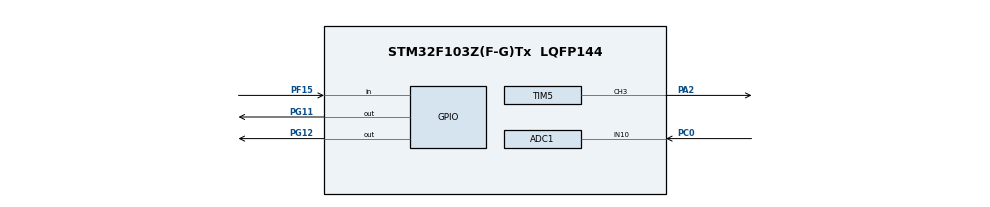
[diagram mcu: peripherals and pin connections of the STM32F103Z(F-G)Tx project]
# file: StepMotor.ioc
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ADC1.Channel-0\#ChannelRegularConversion=ADC_CHANNEL_10
ADC1.NbrOfConversionFlag=1
ADC1.Rank-0\#ChannelRegularConversion=1
ADC1.SamplingTime-0\#ChannelRegularConversion=ADC_SAMPLETIME_1CYCLE_5
ADC1.master=1
Mcu.Family=STM32F1
Mcu.Name=STM32F103Z(F-G)Tx
Mcu.Package=LQFP144
NVIC.PriorityGroup=NVIC_PRIORITYGROUP_4
PA13.Mode=Serial_Wire
PA13.Signal=SYS_JTMS-SWDIO
PA14.Mode=Serial_Wire
PA14.Signal=SYS_JTCK-SWCLK
PA2.Signal=S_TIM5_CH3
PC0.Signal=ADCx_IN10
PF15.Signal=GPIO_Input
PG11.Signal=GPIO_Output
PG12.Signal=GPIO_Output
ProjectManager.HeapSize=0x200
ProjectManager.StackSize=0x400
ProjectManager.TargetToolchain=MDK-ARM V5.27
RCC.APB1Freq_Value=8000000
RCC.APB2Freq_Value=8000000
SH.ADCx_IN10.0=ADC1_IN10,IN10
SH.S_TIM5_CH3.0=TIM5_CH3,PWM Generation3 CH3
TIM5.Channel-PWM\ Generation3\ CH3=TIM_CHANNEL_3
TIM5.Period=200
TIM5.Prescaler=72
board=custom

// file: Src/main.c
/* USER CODE BEGIN Header */
/**
  ******************************************************************************
  * @file           : main.c
  * @brief          : Main program body
  ******************************************************************************
  * @attention
  *
  * <h2><center>&copy; Copyright (c) 2019 STMicroelectronics.
  * All rights reserved.</center></h2>
  *
  * This software component is licensed by ST under BSD 3-Clause license,
  * the "License"; You may not use this file except in compliance with the
  * License. You may obtain a copy of the License at:
  *                        opensource.org/licenses/BSD-3-Clause
  *
  ******************************************************************************
  */
/* USER CODE END Header */

#include "main.h"

ADC_HandleTypeDef hadc1;
TIM_HandleTypeDef htim5;

void SystemClock_Config(void);
static void MX_GPIO_Init(void);
static void MX_ADC1_Init(void);
static void MX_TIM5_Init(void);

int main(void)
{

  /* MCU Configuration--------------------------------------------------------*/

  /* Reset of all peripherals, Initializes the Flash interface and the Systick. */
  HAL_Init();

  /* Configure the system clock */
  SystemClock_Config();

  /* Initialize all configured peripherals */
  MX_GPIO_Init();
  MX_ADC1_Init();
  MX_TIM5_Init();
  /* USER CODE BEGIN 2 */
  HAL_GPIO_WritePin(GPIOG, GPIO_PIN_12, GPIO_PIN_SET);

  HAL_TIM_PWM_Start(&htim5, TIM_CHANNEL_3);
  HAL_TIMEx_PWMN_Start(&htim5, TIM_CHANNEL_3);
  __HAL_TIM_SET_COMPARE(&htim5, TIM_CHANNEL_3, 100);
  /* USER CODE END 2 */

  /* Infinite loop */
  /* USER CODE BEGIN WHILE */
  while (1)
  {
  	HAL_GPIO_WritePin(GPIOG, GPIO_PIN_11, GPIO_PIN_SET);
  	HAL_Delay(1000);
  	HAL_GPIO_WritePin(GPIOG, GPIO_PIN_11, GPIO_PIN_RESET);
  	HAL_Delay(1000);
    /* USER CODE END WHILE */

  }
}

void SystemClock_Config(void)
{
  RCC_OscInitTypeDef RCC_OscInitStruct = {0};
  RCC_ClkInitTypeDef RCC_ClkInitStruct = {0};
  RCC_PeriphCLKInitTypeDef PeriphClkInit = {0};

  /** Initializes the CPU, AHB and APB busses clocks
  */
  RCC_OscInitStruct.OscillatorType = RCC_OSCILLATORTYPE_HSI;
  RCC_OscInitStruct.HSIState = RCC_HSI_ON;
  RCC_OscInitStruct.HSICalibrationValue = RCC_HSICALIBRATION_DEFAULT;
  RCC_OscInitStruct.PLL.PLLState = RCC_PLL_NONE;
  if (HAL_RCC_OscConfig(&RCC_OscInitStruct) != HAL_OK)
  {
    Error_Handler();
  }
  /** Initializes the CPU, AHB and APB busses clocks
  */
  RCC_ClkInitStruct.ClockType = RCC_CLOCKTYPE_HCLK|RCC_CLOCKTYPE_SYSCLK
                              |RCC_CLOCKTYPE_PCLK1|RCC_CLOCKTYPE_PCLK2;
  RCC_ClkInitStruct.SYSCLKSource = RCC_SYSCLKSOURCE_HSI;
  RCC_ClkInitStruct.AHBCLKDivider = RCC_SYSCLK_DIV1;
  RCC_ClkInitStruct.APB1CLKDivider = RCC_HCLK_DIV1;
  RCC_ClkInitStruct.APB2CLKDivider = RCC_HCLK_DIV1;

  if (HAL_RCC_ClockConfig(&RCC_ClkInitStruct, FLASH_LATENCY_0) != HAL_OK)
  {
    Error_Handler();
  }
  PeriphClkInit.PeriphClockSelection = RCC_PERIPHCLK_ADC;
  PeriphClkInit.AdcClockSelection = RCC_ADCPCLK2_DIV2;
  if (HAL_RCCEx_PeriphCLKConfig(&PeriphClkInit) != HAL_OK)
  {
    Error_Handler();
  }
}

static void MX_ADC1_Init(void)
{

  ADC_ChannelConfTypeDef sConfig = {0};

  /** Common config
  */
  hadc1.Instance = ADC1;
  hadc1.Init.ScanConvMode = ADC_SCAN_DISABLE;
  hadc1.Init.ContinuousConvMode = DISABLE;
  hadc1.Init.DiscontinuousConvMode = DISABLE;
  hadc1.Init.ExternalTrigConv = ADC_SOFTWARE_START;
  hadc1.Init.DataAlign = ADC_DATAALIGN_RIGHT;
  hadc1.Init.NbrOfConversion = 1;
  if (HAL_ADC_Init(&hadc1) != HAL_OK)
  {
    Error_Handler();
  }
  /** Configure Regular Channel
  */
  sConfig.Channel = ADC_CHANNEL_10;
  sConfig.Rank = ADC_REGULAR_RANK_1;
  sConfig.SamplingTime = ADC_SAMPLETIME_1CYCLE_5;
  if (HAL_ADC_ConfigChannel(&hadc1, &sConfig) != HAL_OK)
  {
    Error_Handler();
  }

}

static void MX_TIM5_Init(void)
{

  TIM_MasterConfigTypeDef sMasterConfig = {0};
  TIM_OC_InitTypeDef sConfigOC = {0};

  htim5.Instance = TIM5;
  htim5.Init.Prescaler = 72;
  htim5.Init.CounterMode = TIM_COUNTERMODE_UP;
  htim5.Init.Period = 200;
  htim5.Init.ClockDivision = TIM_CLOCKDIVISION_DIV1;
  htim5.Init.AutoReloadPreload = TIM_AUTORELOAD_PRELOAD_DISABLE;
  if (HAL_TIM_PWM_Init(&htim5) != HAL_OK)
  {
    Error_Handler();
  }
  sMasterConfig.MasterOutputTrigger = TIM_TRGO_RESET;
  sMasterConfig.MasterSlaveMode = TIM_MASTERSLAVEMODE_DISABLE;
  if (HAL_TIMEx_MasterConfigSynchronization(&htim5, &sMasterConfig) != HAL_OK)
  {
    Error_Handler();
  }
  sConfigOC.OCMode = TIM_OCMODE_PWM1;
  sConfigOC.Pulse = 0;
  sConfigOC.OCPolarity = TIM_OCPOLARITY_HIGH;
  sConfigOC.OCFastMode = TIM_OCFAST_DISABLE;
  if (HAL_TIM_PWM_ConfigChannel(&htim5, &sConfigOC, TIM_CHANNEL_3) != HAL_OK)
  {
    Error_Handler();
  }
  HAL_TIM_MspPostInit(&htim5);

}

static void MX_GPIO_Init(void)
{
  GPIO_InitTypeDef GPIO_InitStruct = {0};

  /* GPIO Ports Clock Enable */
  __HAL_RCC_GPIOC_CLK_ENABLE();
  __HAL_RCC_GPIOA_CLK_ENABLE();
  __HAL_RCC_GPIOF_CLK_ENABLE();
  __HAL_RCC_GPIOG_CLK_ENABLE();

  /*Configure GPIO pin Output Level */
  HAL_GPIO_WritePin(GPIOG, GPIO_PIN_11|GPIO_PIN_12, GPIO_PIN_RESET);

  /*Configure GPIO pin : PF15 */
  GPIO_InitStruct.Pin = GPIO_PIN_15;
  GPIO_InitStruct.Mode = GPIO_MODE_INPUT;
  GPIO_InitStruct.Pull = GPIO_NOPULL;
  HAL_GPIO_Init(GPIOF, &GPIO_InitStruct);

  /*Configure GPIO pins : PG11 PG12 */
  GPIO_InitStruct.Pin = GPIO_PIN_11|GPIO_PIN_12;
  GPIO_InitStruct.Mode = GPIO_MODE_OUTPUT_PP;
  GPIO_InitStruct.Pull = GPIO_NOPULL;
  GPIO_InitStruct.Speed = GPIO_SPEED_FREQ_LOW;
  HAL_GPIO_Init(GPIOG, &GPIO_InitStruct);

}

void Error_Handler(void)
{
}

/************************ (C) COPYRIGHT STMicroelectronics *****END OF FILE****/
